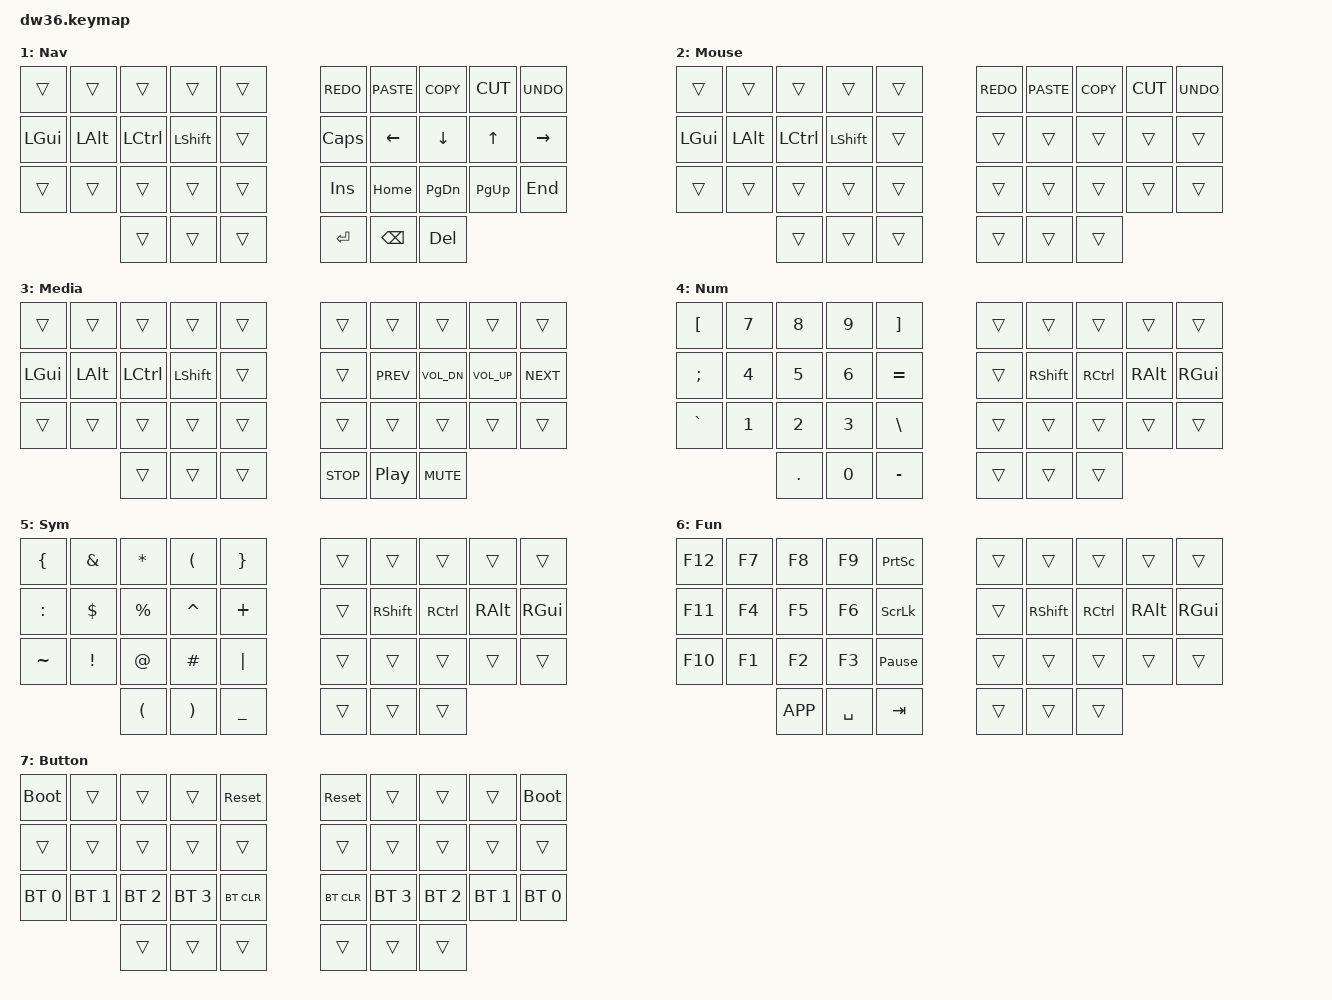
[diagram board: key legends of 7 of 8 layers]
/*
 * Copyright (c) 2020 The ZMK Contributors
 *
 * SPDX-License-Identifier: MIT
 */

#include <behaviors.dtsi>
#include <dt-bindings/zmk/keys.h>
#include <dt-bindings/zmk/bt.h>

// Miryoku home row mods
#define HRML(k1,k2,k3,k4) &ht LGUI k1  &ht LALT k2  &ht LCTRL k3  &ht LSHFT k4
#define HRMR(k1,k2,k3,k4) &ht RSHFT k1  &ht RCTRL k2  &ht RALT k3  &ht RGUI k4

/ {
    behaviors {
        ht: hold_tap {
            compatible = "zmk,behavior-hold-tap";
            #binding-cells = <2>;
            flavor = "tap-preferred";
            tapping-term-ms = <220>;
            quick-tap-ms = <150>;
            require-prior-idle-ms = <100>;
            bindings = <&kp>, <&kp>;
        };
    };

    keymap {
        compatible = "zmk,keymap";

        // Colemak-DH Base Layer
        default_layer {
            display-name = "Base";
// -----------------------------------------------------------------------------------------
// |  Q  |  W  |  F  |  P  |  B  |   |  J  |  L  |  U  |  Y  | ' " |
// |  A  |  R  |  S  |  T  |  G  |   |  M  |  N  |  E  |  I  |  O  |
// |  Z  |  X  |  C  |  D  |  V  |   |  K  |  H  | , < | . > | / ? |
//             | ESC | SPC | TAB |   | ENT | BSPC| DEL |
            bindings = <
   &kp Q  &kp W  &kp F  &kp P  &kp B    &kp J  &kp L  &kp U     &kp Y   &kp SQT
   HRML(A,    R,     S,     T) &kp G    &kp M  HRMR(N,    E,     I,      O)
   &kp Z  &kp X  &kp C  &kp D  &kp V    &kp K  &kp H  &kp COMMA &kp DOT &kp FSLH
              &lt 3 ESC &lt 1 SPACE &lt 4 TAB    &lt 5 RET &lt 2 BSPC &lt 6 DEL
            >;
        };

        // Nav Layer
        nav_layer {
            display-name = "Nav";
// -----------------------------------------------------------------------------------------
// |     |     |     |     |     |   | Redo| Paste| Copy| Cut | Undo|
// | GUI | Alt | Ctrl| Shft|     |   | CapsL| Left| Down|  Up | Right|
// |     |     |     |     |     |   | Ins | Home| PgDn| PgUp| End |
//             |     |     |     |   | Ent | Bspc| Del |
            bindings = <
   &trans &trans &trans &trans &trans    &kp K_REDO &kp K_PASTE &kp K_COPY &kp K_CUT &kp K_UNDO
   &kp LGUI &kp LALT &kp LCTRL &kp LSHFT &trans    &kp CAPS &kp LEFT &kp DOWN &kp UP &kp RIGHT
   &trans &trans &trans &trans &trans    &kp INS &kp HOME &kp PG_DN &kp PG_UP &kp END
              &trans &trans &trans    &kp RET &kp BSPC &kp DEL
            >;
        };

        // Mouse Layer
        mouse_layer {
            display-name = "Mouse";
// -----------------------------------------------------------------------------------------
// |     |     |     |     |     |   | Redo| Paste| Copy| Cut | Undo|
// | GUI | Alt | Ctrl| Shft|     |   |     |     |     |     |     |
// |     |     |     |     |     |   |     |     |     |     |     |
//             |     |     |     |   | Btn2| Btn1| Btn3|
            bindings = <
   &trans &trans &trans &trans &trans    &kp K_REDO &kp K_PASTE &kp K_COPY &kp K_CUT &kp K_UNDO
   &kp LGUI &kp LALT &kp LCTRL &kp LSHFT &trans    &trans &trans &trans &trans &trans
   &trans &trans &trans &trans &trans    &trans &trans &trans &trans &trans
              &trans &trans &trans    &trans &trans &trans
            >;
        };

        // Media Layer (3)
        media_layer {
            display-name = "Media";
// -----------------------------------------------------------------------------------------
// |     |     |     |     |     |   |     |     |     |     |     |
// | GUI | Alt | Ctrl| Shft|     |   |     | Prev| VolDn| VolUp| Next|
// |     |     |     |     |     |   |     |     |     |     |     |
//             |     |     |     |   | Stop| Play| Mute|
            bindings = <
   &trans &trans &trans &trans &trans    &trans &trans &trans &trans &trans
   &kp LGUI &kp LALT &kp LCTRL &kp LSHFT &trans    &trans &kp C_PREV &kp C_VOL_DN &kp C_VOL_UP &kp C_NEXT
   &trans &trans &trans &trans &trans    &trans &trans &trans &trans &trans
              &trans &trans &trans    &kp C_STOP &kp C_PP &kp C_MUTE
            >;
        };

        // Num Layer (4)  
        num_layer {
            display-name = "Num";
// -----------------------------------------------------------------------------------------
// | [ { | 7 & | 8 * | 9 ( | ] } |   |     |     |     |     |     |
// | ; : | 4 $ | 5 % | 6 ^ | = + |   |     | Shft| Ctrl| Alt | GUI |
// | ` ~ | 1 ! | 2 @ | 3 # | \ | |   |     |     |     |     |     |
//             | . > | 0 ) | - _ |   |     |     |     |
            bindings = <
   &kp LBKT &kp N7 &kp N8 &kp N9 &kp RBKT    &trans &trans &trans &trans &trans
   &kp SEMI &kp N4 &kp N5 &kp N6 &kp EQUAL   &trans &kp RSHFT &kp RCTRL &kp RALT &kp RGUI
   &kp GRAVE &kp N1 &kp N2 &kp N3 &kp BSLH   &trans &trans &trans &trans &trans
              &kp DOT &kp N0 &kp MINUS    &trans &trans &trans
            >;
        };

        // Sym Layer (5)
        sym_layer {
            display-name = "Sym";
// -----------------------------------------------------------------------------------------
// | { [ | & 7 | * 8 | ( 9 | } ] |   |     |     |     |     |     |
// | : ; | $ 4 | % 5 | ^ 6 | + = |   |     | Shft| Ctrl| Alt | GUI |
// | ~ ` | ! 1 | @ 2 | # 3 | | \ |   |     |     |     |     |     |
//             | ( 9 | ) 0 | _ - |   |     |     |     |
            bindings = <
   &kp LBRC &kp AMPS &kp ASTRK &kp LPAR &kp RBRC    &trans &trans &trans &trans &trans
   &kp COLON &kp DLLR &kp PRCNT &kp CARET &kp PLUS   &trans &kp RSHFT &kp RCTRL &kp RALT &kp RGUI
   &kp TILDE &kp EXCL &kp AT &kp HASH &kp PIPE      &trans &trans &trans &trans &trans
              &kp LPAR &kp RPAR &kp UNDER    &trans &trans &trans
            >;
        };

        // Fun Layer (6)
        fun_layer {
            display-name = "Fun";
// -----------------------------------------------------------------------------------------
// | F12 | F7  | F8  | F9  | PrtSc|   |     |     |     |     |     |
// | F11 | F4  | F5  | F6  | SLock|   |     | Shft| Ctrl| Alt | GUI |
// | F10 | F1  | F2  | F3  | Pause|   |     |     |     |     |     |
//             | App | Spc | Tab  |   |     |     |     |
            bindings = <
   &kp F12 &kp F7 &kp F8 &kp F9 &kp PSCRN    &trans &trans &trans &trans &trans
   &kp F11 &kp F4 &kp F5 &kp F6 &kp SLCK     &trans &kp RSHFT &kp RCTRL &kp RALT &kp RGUI
   &kp F10 &kp F1 &kp F2 &kp F3 &kp PAUSE_BREAK    &trans &trans &trans &trans &trans
              &kp K_APP &kp SPACE &kp TAB    &trans &trans &trans
            >;
        };

        // Button Layer (7)
        button_layer {
            display-name = "Button";
// -----------------------------------------------------------------------------------------
// |BOOTL|     |     |     |RESET|   |RESET|     |     |     |BOOTL|
// |     |     |     |     |     |   |     |     |     |     |     |
// | BT1 | BT2 | BT3 | BT4 | BTCLR|   |BTCLR| BT4 | BT3 | BT2 | BT1 |
//             |     |     |     |   |     |     |     |
            bindings = <
   &bootloader &trans &trans &trans &sys_reset    &sys_reset &trans &trans &trans &bootloader
   &trans &trans &trans &trans &trans    &trans &trans &trans &trans &trans
   &bt BT_SEL 0 &bt BT_SEL 1 &bt BT_SEL 2 &bt BT_SEL 3 &bt BT_CLR    &bt BT_CLR &bt BT_SEL 3 &bt BT_SEL 2 &bt BT_SEL 1 &bt BT_SEL 0
              &trans &trans &trans    &trans &trans &trans
            >;
        };
    };

    conditional_layers {
        compatible = "zmk,conditional-layers";
        tri_layer {
            if-layers = <1 2>;
            then-layer = <7>;
        };
    };
};
